VERSION ""

NS_ :

BS_:

BU_: SIM ECU TESTER

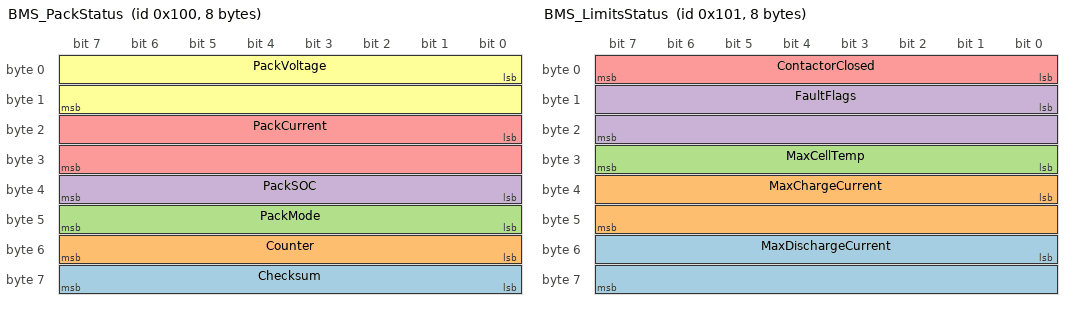
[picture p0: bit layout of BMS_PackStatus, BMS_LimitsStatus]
BO_ 256 BMS_PackStatus: 8 ECU
 SG_ Checksum : 56|8@1+ (1,0) [0.0|255.0] ""  TESTER
 SG_ Counter : 48|8@1+ (1,0) [0.0|255.0] ""  TESTER
 SG_ PackMode : 40|8@1+ (1,0) [0.0|255.0] "enum"  TESTER
 SG_ PackSOC : 32|8@1+ (0.5,0.0) [0.0|127.5] "%"  TESTER
 SG_ PackCurrent : 16|16@1+ (0.1,-3276.8) [-3276.8|3276.7] "A"  TESTER
 SG_ PackVoltage : 0|16@1+ (0.1,0.0) [0.0|6553.5] "V"  TESTER

BO_ 257 BMS_LimitsStatus: 8 ECU
 SG_ MaxDischargeCurrent : 48|16@1+ (0.1,0.0) [0.0|6553.5] "A"  TESTER
 SG_ MaxChargeCurrent : 32|16@1+ (0.1,0.0) [0.0|6553.5] "A"  TESTER
 SG_ MaxCellTemp : 24|8@1+ (1,-40) [-40.0|215.0] "degC"  TESTER
 SG_ FaultFlags : 8|16@1+ (1,0) [0.0|65535.0] "bitfield"  TESTER
 SG_ ContactorClosed : 0|8@1+ (1,0) [0.0|255.0] "bool"  TESTER

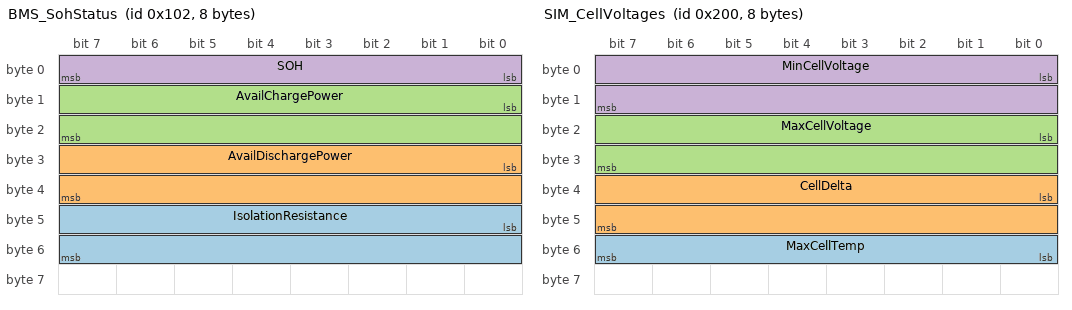
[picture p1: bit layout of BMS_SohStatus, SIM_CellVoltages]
BO_ 258 BMS_SohStatus: 8 ECU
 SG_ IsolationResistance : 40|16@1+ (1,0) [0.0|65535.0] "kOhm"  TESTER
 SG_ AvailDischargePower : 24|16@1+ (0.01,0.0) [0.0|655.35] "kW"  TESTER
 SG_ AvailChargePower : 8|16@1+ (0.01,0.0) [0.0|655.35] "kW"  TESTER
 SG_ SOH : 0|8@1+ (0.5,0.0) [0.0|127.5] "%"  TESTER

BO_ 512 SIM_CellVoltages: 8 SIM
 SG_ MaxCellTemp : 48|8@1+ (1,-40) [-40.0|215.0] "degC"  ECU
 SG_ CellDelta : 32|16@1+ (0.001,0.0) [0.0|65.535] "V"  ECU
 SG_ MaxCellVoltage : 16|16@1+ (0.001,0.0) [0.0|65.535] "V"  ECU
 SG_ MinCellVoltage : 0|16@1+ (0.001,0.0) [0.0|65.535] "V"  ECU

BO_ 513 SIM_IsolationStatus: 8 SIM
 SG_ IsolationResistance : 0|16@1+ (1,0) [0.0|65535.0] "kOhm"  ECU

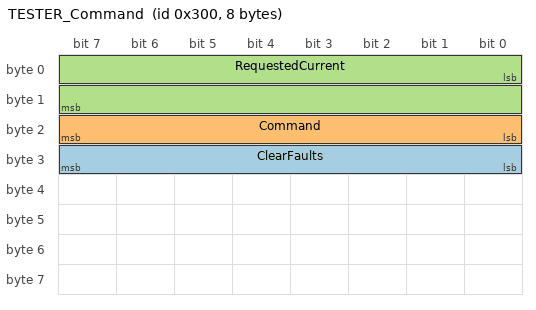
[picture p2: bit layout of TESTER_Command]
BO_ 768 TESTER_Command: 8 TESTER
 SG_ ClearFaults : 24|8@1+ (1,0) [0.0|255.0] "bool"  ECU
 SG_ Command : 16|8@1+ (1,0) [0.0|255.0] "enum"  ECU
 SG_ RequestedCurrent : 0|16@1+ (0.1,-3276.8) [-3276.8|3276.7] "A"  ECU

CM_ BO_ 256 "BMS_PackStatus demonstration message";
CM_ BO_ 257 "BMS_LimitsStatus demonstration message";
CM_ BO_ 258 "BMS_SohStatus demonstration message";
CM_ BO_ 512 "SIM_CellVoltages demonstration message";
CM_ BO_ 513 "SIM_IsolationStatus demonstration message";
CM_ BO_ 768 "TESTER_Command demonstration message";
